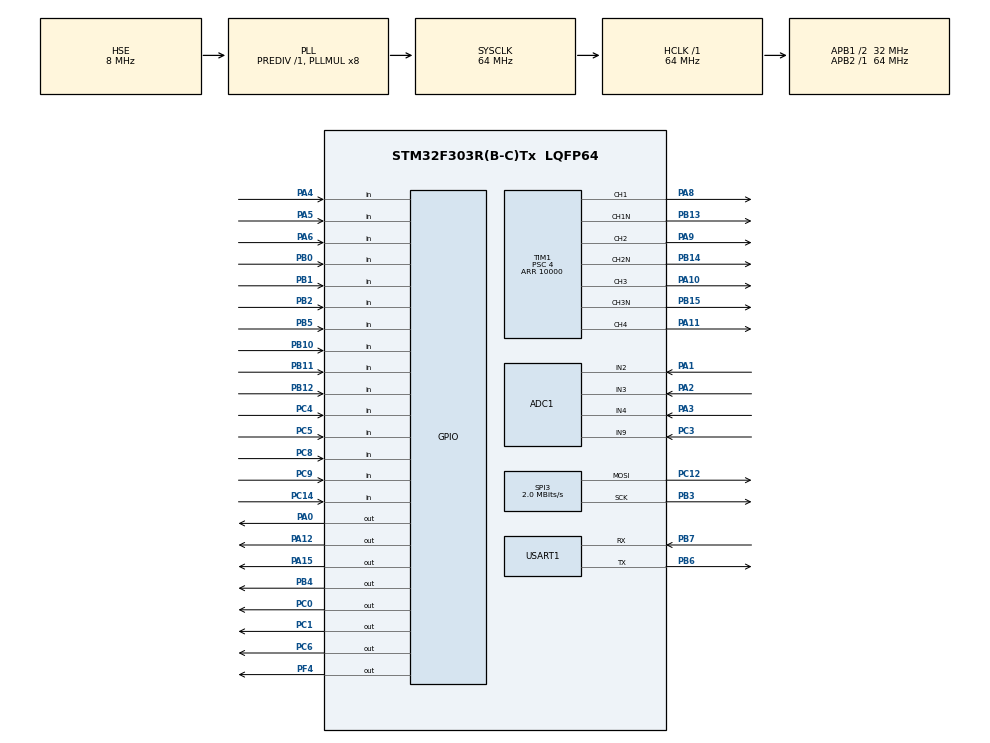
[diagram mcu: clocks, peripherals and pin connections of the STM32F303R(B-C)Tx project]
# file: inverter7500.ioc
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ADC1.Channel-1\#ChannelRegularConversion=ADC_CHANNEL_2
ADC1.ContinuousConvMode=ENABLE
ADC1.NbrOfConversionFlag=1
ADC1.Offset-1\#ChannelRegularConversion=0
ADC1.OffsetNumber-1\#ChannelRegularConversion=ADC_OFFSET_NONE
ADC1.Rank-1\#ChannelRegularConversion=1
ADC1.SamplingTime-1\#ChannelRegularConversion=ADC_SAMPLETIME_1CYCLE_5
ADC1.master=1
Mcu.Family=STM32F3
Mcu.Name=STM32F303R(B-C)Tx
Mcu.Package=LQFP64
NVIC.ADC1_2_IRQn=true\:0\:0\:false\:false\:true\:true\:true
NVIC.PriorityGroup=NVIC_PRIORITYGROUP_4
NVIC.SPI3_IRQn=true\:0\:0\:false\:false\:true\:true\:true
NVIC.TIM1_UP_TIM16_IRQn=true\:0\:0\:false\:false\:true\:true\:true
NVIC.TIM6_DAC_IRQn=true\:0\:0\:false\:false\:true\:true\:true
PA0.Signal=GPIO_Output
PA1.Mode=IN2-Single-Ended
PA1.Signal=ADC1_IN2
PA10.Signal=S_TIM1_CH3
PA11.Signal=S_TIM1_CH4
PA12.Signal=GPIO_Output
PA15.Signal=GPIO_Output
PA2.Mode=IN3-Single-Ended
PA2.Signal=ADC1_IN3
PA3.Mode=IN4-Single-Ended
PA3.Signal=ADC1_IN4
PA4.Signal=GPIO_Input
PA5.Signal=GPIO_Input
PA6.Signal=GPIO_Input
PA8.Signal=S_TIM1_CH1
PA9.Signal=S_TIM1_CH2
PB0.Signal=GPIO_Input
PB1.Signal=GPIO_Input
PB10.Signal=GPIO_Input
PB11.Signal=GPIO_Input
PB12.Signal=GPIO_Input
PB13.Mode=PWM Generation1 CH1 CH1N
PB13.Signal=TIM1_CH1N
PB14.Mode=PWM Generation2 CH2 CH2N
PB14.Signal=TIM1_CH2N
PB15.Mode=PWM Generation3 CH3 CH3N
PB15.Signal=TIM1_CH3N
PB2.Signal=GPIO_Input
PB3.Mode=TX_Only_Simplex_Unidirect_Master
PB3.Signal=SPI3_SCK
PB4.Signal=GPIO_Output
PB5.Signal=GPIO_Input
PB6.Mode=Asynchronous
PB6.Signal=USART1_TX
PB7.Mode=Asynchronous
PB7.Signal=USART1_RX
PC0.Signal=GPIO_Output
PC1.Signal=GPIO_Output
PC12.Mode=TX_Only_Simplex_Unidirect_Master
PC12.Signal=SPI3_MOSI
PC14-OSC32_IN.Signal=GPIO_Input
PC3.Signal=ADCx_IN9
PC4.Signal=GPIO_Input
PC5.Signal=GPIO_Input
PC6.Signal=GPIO_Output
PC8.Signal=GPIO_Input
PC9.Signal=GPIO_Input
PF0-OSC_IN.Mode=HSE-External-Oscillator
PF0-OSC_IN.Signal=RCC_OSC_IN
PF1-OSC_OUT.Mode=HSE-External-Oscillator
PF1-OSC_OUT.Signal=RCC_OSC_OUT
PF4.Signal=GPIO_Output
ProjectManager.HeapSize=0x200
ProjectManager.StackSize=0x400
ProjectManager.TargetToolchain=EWARM V8
RCC.AHBFreq_Value=64000000
RCC.APB1CLKDivider=RCC_HCLK_DIV2
RCC.APB1Freq_Value=32000000
RCC.APB1TimFreq_Value=64000000
RCC.APB2Freq_Value=64000000
RCC.APB2TimFreq_Value=64000000
RCC.CortexFreq_Value=64000000
RCC.EnbaleCSS=true
RCC.HCLKFreq_Value=64000000
RCC.HSE_VALUE=8000000
RCC.HSI_VALUE=8000000
RCC.LSE_VALUE=32768
RCC.PLLMUL=RCC_PLL_MUL8
RCC.PLLSourceVirtual=RCC_PLLSOURCE_HSE
RCC.SYSCLKFreq_VALUE=64000000
RCC.SYSCLKSourceVirtual=RCC_SYSCLKSOURCE_PLLCLK
RCC.USBFreq_Value=64000000
SH.ADCx_IN9.0=ADC1_IN9,IN9-Single-Ended
SH.S_TIM1_CH1.0=TIM1_CH1,PWM Generation1 CH1 CH1N
SH.S_TIM1_CH2.0=TIM1_CH2,PWM Generation2 CH2 CH2N
SH.S_TIM1_CH3.0=TIM1_CH3,PWM Generation3 CH3 CH3N
SH.S_TIM1_CH4.0=TIM1_CH4,PWM Generation4 CH4
SPI3.BaudRatePrescaler=SPI_BAUDRATEPRESCALER_16
SPI3.CLKPhase=SPI_PHASE_1EDGE
SPI3.CLKPolarity=SPI_POLARITY_LOW
SPI3.CalculateBaudRate=2.0 MBits/s
SPI3.DataSize=SPI_DATASIZE_8BIT
SPI3.Direction=SPI_DIRECTION_2LINES
SPI3.Mode=SPI_MODE_MASTER
SPI3.NSSPMode=SPI_NSS_PULSE_DISABLE
SPI3.VirtualType=VM_MASTER
TIM1.AutomaticOutput=TIM_AUTOMATICOUTPUT_DISABLE
TIM1.BreakState=TIM_BREAK_DISABLE
TIM1.Channel-PWM\ Generation1\ CH1\ CH1N=TIM_CHANNEL_1
TIM1.Channel-PWM\ Generation2\ CH2\ CH2N=TIM_CHANNEL_2
TIM1.Channel-PWM\ Generation3\ CH3\ CH3N=TIM_CHANNEL_3
TIM1.Channel-PWM\ Generation4\ CH4=TIM_CHANNEL_4
TIM1.CounterMode=TIM_COUNTERMODE_CENTERALIGNED1
TIM1.Period=10000
TIM1.Prescaler=4
TIM6.AutoReloadPreload=TIM_AUTORELOAD_PRELOAD_ENABLE
TIM6.Period=64000
TIM6.Prescaler=0
TIM6.TIM_MasterOutputTrigger=TIM_TRGO_RESET
USART1.VirtualMode-Asynchronous=VM_ASYNC
VP_TIM1_VS_ClockSourceINT.Mode=Internal
VP_TIM6_VS_ClockSourceINT.Mode=Enable_Timer
board=custom

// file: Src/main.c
// linking branch edit
/* USER CODE BEGIN Header */
/**
  ******************************************************************************
  * @file           : main.c
  * @brief          : Main program body
  ******************************************************************************
  * @attention
  *
  * <h2><center>&copy; Copyright (c) 2019 STMicroelectronics.
  * All rights reserved.</center></h2>
  *
  * This software component is licensed by ST under BSD 3-Clause license,
  * the "License"; You may not use this file except in compliance with the
  * License. You may obtain a copy of the License at:
  *                        opensource.org/licenses/BSD-3-Clause
  *
  ******************************************************************************
  */
/* USER CODE END Header */ //master edit

#include "main.h"

/* USER CODE BEGIN Includes */
#include "MOTOR\motor_control.h"
/* USER CODE END Includes */

ADC_HandleTypeDef hadc1;

SPI_HandleTypeDef hspi3;

TIM_HandleTypeDef htim1;
TIM_HandleTypeDef htim6;

UART_HandleTypeDef huart1;

void SystemClock_Config(void);
static void MX_GPIO_Init(void);
static void MX_ADC1_Init(void);
static void MX_TIM1_Init(void);
static void MX_TIM6_Init(void);
static void MX_USART1_UART_Init(void);
static void MX_SPI3_Init(void);

int main(void)
{

  /* MCU Configuration--------------------------------------------------------*/

  /* Reset of all peripherals, Initializes the Flash interface and the Systick. */
  HAL_Init();

  /* Configure the system clock */
  SystemClock_Config();

  /* Initialize all configured peripherals */
  MX_GPIO_Init();
  MX_ADC1_Init();
  MX_TIM1_Init();
  MX_TIM6_Init();
  MX_USART1_UART_Init();
  MX_SPI3_Init();
  /* USER CODE BEGIN 2 */

  GPIO_InitTypeDef GPIO_InitStruct = {0};
/*Configure GPIO pin : PB4 */
  GPIO_InitStruct.Pin = GPIO_PIN_4;
  GPIO_InitStruct.Mode = GPIO_MODE_OUTPUT_OD;
  GPIO_InitStruct.Pull = GPIO_NOPULL;
  GPIO_InitStruct.Speed = GPIO_SPEED_FREQ_LOW;
  HAL_GPIO_Init(GPIOB, &GPIO_InitStruct);

  HAL_TIM_Base_Start_IT(&htim6);

  /* USER CODE END 2 */

  /* Infinite loop */
  /* USER CODE BEGIN WHILE */
  //GPIOC_OTYPER=GPIOC_OTYPER | 0x100;
//  led_7segment_data[2]=0x1F;
  led_7segment_data[1]=0x0F;
  led_7segment_data[0]=0x0F;

  while (1)
  {

  //HAL_GPIO_TogglePin (GPIOF, GPIO_PIN_4);

  //  HAL_GPIO_WritePin(GPIOF, GPIO_PIN_4, GPIO_PIN_RESET);
  //HAL_Delay (1000);
  // HAL_GPIO_WritePin(GPIOF, GPIO_PIN_4, GPIO_PIN_SET);
  // HAL_Delay(1000);
  //  highbit_led_7segment_data=0x77;
  //HAL_GPIO_TogglePin(GPIOB, GPIO_PIN_4);
  //  HAL_Delay(10);
 // HAL_SPI_Transmit_IT(&hspi3, (uint8_t*) (led_7segment_data), 2);

  HAL_SPI_Transmit_IT(&hspi3, &led_7segment_data[0], 1);
   //   HAL_Delay(1);
  HAL_GPIO_WritePin(GPIOF, GPIO_PIN_4, GPIO_PIN_SET);
  //HAL_GPIO_WritePin(GPIOF, GPIO_PIN_4, GPIO_PIN_RESET);
  HAL_SPI_Transmit_IT(&hspi3, &led_7segment_data[1], 1);
//  HAL_GPIO_WritePin(GPIOF, GPIO_PIN_4, GPIO_PIN_SET);
  HAL_GPIO_WritePin(GPIOF, GPIO_PIN_4, GPIO_PIN_RESET);

  //HAL_GPIO_TogglePin(GPIOF, GPIO_PIN_4);
  //  HAL_Delay(1);
  //HAL_GPIO_WritePin(GPIOB, GPIO_PIN_4, GPIO_PIN_SET);
  //HAL_Delay(1);

  //HAL_Delay(1);

  //  if (highbit_led_7segment_data==0xAA) highbit_led_7segment_data=0x55;
  // else highbit_led_7segment_data=0xAA;

    /* USER CODE END WHILE */

  }
}

void SystemClock_Config(void)
{
  RCC_OscInitTypeDef RCC_OscInitStruct = {0};
  RCC_ClkInitTypeDef RCC_ClkInitStruct = {0};
  RCC_PeriphCLKInitTypeDef PeriphClkInit = {0};

  /** Initializes the CPU, AHB and APB busses clocks
  */
  RCC_OscInitStruct.OscillatorType = RCC_OSCILLATORTYPE_HSE;
  RCC_OscInitStruct.HSEState = RCC_HSE_ON;
  RCC_OscInitStruct.HSEPredivValue = RCC_HSE_PREDIV_DIV1;
  RCC_OscInitStruct.HSIState = RCC_HSI_ON;
  RCC_OscInitStruct.PLL.PLLState = RCC_PLL_ON;
  RCC_OscInitStruct.PLL.PLLSource = RCC_PLLSOURCE_HSE;
  RCC_OscInitStruct.PLL.PLLMUL = RCC_PLL_MUL8;
  if (HAL_RCC_OscConfig(&RCC_OscInitStruct) != HAL_OK)
  {
    Error_Handler();
  }
  /** Initializes the CPU, AHB and APB busses clocks
  */
  RCC_ClkInitStruct.ClockType = RCC_CLOCKTYPE_HCLK|RCC_CLOCKTYPE_SYSCLK
                              |RCC_CLOCKTYPE_PCLK1|RCC_CLOCKTYPE_PCLK2;
  RCC_ClkInitStruct.SYSCLKSource = RCC_SYSCLKSOURCE_PLLCLK;
  RCC_ClkInitStruct.AHBCLKDivider = RCC_SYSCLK_DIV1;
  RCC_ClkInitStruct.APB1CLKDivider = RCC_HCLK_DIV2;
  RCC_ClkInitStruct.APB2CLKDivider = RCC_HCLK_DIV1;

  if (HAL_RCC_ClockConfig(&RCC_ClkInitStruct, FLASH_LATENCY_2) != HAL_OK)
  {
    Error_Handler();
  }
  PeriphClkInit.PeriphClockSelection = RCC_PERIPHCLK_USART1|RCC_PERIPHCLK_TIM1
                              |RCC_PERIPHCLK_ADC12;
  PeriphClkInit.Usart1ClockSelection = RCC_USART1CLKSOURCE_PCLK2;
  PeriphClkInit.Adc12ClockSelection = RCC_ADC12PLLCLK_DIV1;
  PeriphClkInit.Tim1ClockSelection = RCC_TIM1CLK_HCLK;
  if (HAL_RCCEx_PeriphCLKConfig(&PeriphClkInit) != HAL_OK)
  {
    Error_Handler();
  }
  /** Enables the Clock Security System
  */
  HAL_RCC_EnableCSS();
}

static void MX_ADC1_Init(void)
{

  ADC_MultiModeTypeDef multimode = {0};
  ADC_ChannelConfTypeDef sConfig = {0};

  /** Common config
  */
  hadc1.Instance = ADC1;
  hadc1.Init.ClockPrescaler = ADC_CLOCK_ASYNC_DIV1;
  hadc1.Init.Resolution = ADC_RESOLUTION_12B;
  hadc1.Init.ScanConvMode = ADC_SCAN_DISABLE;
  hadc1.Init.ContinuousConvMode = ENABLE;
  hadc1.Init.DiscontinuousConvMode = DISABLE;
  hadc1.Init.ExternalTrigConvEdge = ADC_EXTERNALTRIGCONVEDGE_NONE;
  hadc1.Init.ExternalTrigConv = ADC_SOFTWARE_START;
  hadc1.Init.DataAlign = ADC_DATAALIGN_RIGHT;
  hadc1.Init.NbrOfConversion = 1;
  hadc1.Init.DMAContinuousRequests = DISABLE;
  hadc1.Init.EOCSelection = ADC_EOC_SINGLE_CONV;
  hadc1.Init.LowPowerAutoWait = DISABLE;
  hadc1.Init.Overrun = ADC_OVR_DATA_OVERWRITTEN;
  if (HAL_ADC_Init(&hadc1) != HAL_OK)
  {
    Error_Handler();
  }
  /** Configure the ADC multi-mode
  */
  multimode.Mode = ADC_MODE_INDEPENDENT;
  if (HAL_ADCEx_MultiModeConfigChannel(&hadc1, &multimode) != HAL_OK)
  {
    Error_Handler();
  }
  /** Configure Regular Channel
  */
  sConfig.Channel = ADC_CHANNEL_2;
  sConfig.Rank = ADC_REGULAR_RANK_1;
  sConfig.SingleDiff = ADC_SINGLE_ENDED;
  sConfig.SamplingTime = ADC_SAMPLETIME_1CYCLE_5;
  sConfig.OffsetNumber = ADC_OFFSET_NONE;
  sConfig.Offset = 0;
  if (HAL_ADC_ConfigChannel(&hadc1, &sConfig) != HAL_OK)
  {
    Error_Handler();
  }

}

static void MX_SPI3_Init(void)
{

  /* SPI3 parameter configuration*/
  hspi3.Instance = SPI3;
  hspi3.Init.Mode = SPI_MODE_MASTER;
  hspi3.Init.Direction = SPI_DIRECTION_2LINES;
  hspi3.Init.DataSize = SPI_DATASIZE_8BIT;
  hspi3.Init.CLKPolarity = SPI_POLARITY_LOW;
  hspi3.Init.CLKPhase = SPI_PHASE_1EDGE;
  hspi3.Init.NSS = SPI_NSS_SOFT;
  hspi3.Init.BaudRatePrescaler = SPI_BAUDRATEPRESCALER_16;
  hspi3.Init.FirstBit = SPI_FIRSTBIT_MSB;
  hspi3.Init.TIMode = SPI_TIMODE_DISABLE;
  hspi3.Init.CRCCalculation = SPI_CRCCALCULATION_DISABLE;
  hspi3.Init.CRCPolynomial = 7;
  hspi3.Init.CRCLength = SPI_CRC_LENGTH_DATASIZE;
  hspi3.Init.NSSPMode = SPI_NSS_PULSE_DISABLE;
  if (HAL_SPI_Init(&hspi3) != HAL_OK)
  {
    Error_Handler();
  }

}

static void MX_TIM1_Init(void)
{

  TIM_ClockConfigTypeDef sClockSourceConfig = {0};
  TIM_MasterConfigTypeDef sMasterConfig = {0};
  TIM_OC_InitTypeDef sConfigOC = {0};
  TIM_BreakDeadTimeConfigTypeDef sBreakDeadTimeConfig = {0};

  htim1.Instance = TIM1;
  htim1.Init.Prescaler = 4;
  htim1.Init.CounterMode = TIM_COUNTERMODE_CENTERALIGNED1;
  htim1.Init.Period = 10000;
  htim1.Init.ClockDivision = TIM_CLOCKDIVISION_DIV1;
  htim1.Init.RepetitionCounter = 0;
  htim1.Init.AutoReloadPreload = TIM_AUTORELOAD_PRELOAD_DISABLE;
  if (HAL_TIM_Base_Init(&htim1) != HAL_OK)
  {
    Error_Handler();
  }
  sClockSourceConfig.ClockSource = TIM_CLOCKSOURCE_INTERNAL;
  if (HAL_TIM_ConfigClockSource(&htim1, &sClockSourceConfig) != HAL_OK)
  {
    Error_Handler();
  }
  if (HAL_TIM_PWM_Init(&htim1) != HAL_OK)
  {
    Error_Handler();
  }
  sMasterConfig.MasterOutputTrigger = TIM_TRGO_RESET;
  sMasterConfig.MasterOutputTrigger2 = TIM_TRGO2_RESET;
  sMasterConfig.MasterSlaveMode = TIM_MASTERSLAVEMODE_DISABLE;
  if (HAL_TIMEx_MasterConfigSynchronization(&htim1, &sMasterConfig) != HAL_OK)
  {
    Error_Handler();
  }
  sConfigOC.OCMode = TIM_OCMODE_PWM1;
  sConfigOC.Pulse = 0;
  sConfigOC.OCPolarity = TIM_OCPOLARITY_HIGH;
  sConfigOC.OCNPolarity = TIM_OCNPOLARITY_HIGH;
  sConfigOC.OCFastMode = TIM_OCFAST_DISABLE;
  sConfigOC.OCIdleState = TIM_OCIDLESTATE_RESET;
  sConfigOC.OCNIdleState = TIM_OCNIDLESTATE_RESET;
  if (HAL_TIM_PWM_ConfigChannel(&htim1, &sConfigOC, TIM_CHANNEL_1) != HAL_OK)
  {
    Error_Handler();
  }
  if (HAL_TIM_PWM_ConfigChannel(&htim1, &sConfigOC, TIM_CHANNEL_2) != HAL_OK)
  {
    Error_Handler();
  }
  if (HAL_TIM_PWM_ConfigChannel(&htim1, &sConfigOC, TIM_CHANNEL_3) != HAL_OK)
  {
    Error_Handler();
  }
  if (HAL_TIM_PWM_ConfigChannel(&htim1, &sConfigOC, TIM_CHANNEL_4) != HAL_OK)
  {
    Error_Handler();
  }
  sBreakDeadTimeConfig.OffStateRunMode = TIM_OSSR_DISABLE;
  sBreakDeadTimeConfig.OffStateIDLEMode = TIM_OSSI_DISABLE;
  sBreakDeadTimeConfig.LockLevel = TIM_LOCKLEVEL_OFF;
  sBreakDeadTimeConfig.DeadTime = 0;
  sBreakDeadTimeConfig.BreakState = TIM_BREAK_DISABLE;
  sBreakDeadTimeConfig.BreakPolarity = TIM_BREAKPOLARITY_HIGH;
  sBreakDeadTimeConfig.BreakFilter = 0;
  sBreakDeadTimeConfig.Break2State = TIM_BREAK2_DISABLE;
  sBreakDeadTimeConfig.Break2Polarity = TIM_BREAK2POLARITY_HIGH;
  sBreakDeadTimeConfig.Break2Filter = 0;
  sBreakDeadTimeConfig.AutomaticOutput = TIM_AUTOMATICOUTPUT_DISABLE;
  if (HAL_TIMEx_ConfigBreakDeadTime(&htim1, &sBreakDeadTimeConfig) != HAL_OK)
  {
    Error_Handler();
  }
  HAL_TIM_MspPostInit(&htim1);

}

static void MX_TIM6_Init(void)
{

  TIM_MasterConfigTypeDef sMasterConfig = {0};

  htim6.Instance = TIM6;
  htim6.Init.Prescaler = 0;
  htim6.Init.CounterMode = TIM_COUNTERMODE_UP;
  htim6.Init.Period = 64000;
  htim6.Init.AutoReloadPreload = TIM_AUTORELOAD_PRELOAD_ENABLE;
  if (HAL_TIM_Base_Init(&htim6) != HAL_OK)
  {
    Error_Handler();
  }
  sMasterConfig.MasterOutputTrigger = TIM_TRGO_RESET;
  sMasterConfig.MasterSlaveMode = TIM_MASTERSLAVEMODE_DISABLE;
  if (HAL_TIMEx_MasterConfigSynchronization(&htim6, &sMasterConfig) != HAL_OK)
  {
    Error_Handler();
  }

}

static void MX_USART1_UART_Init(void)
{

  huart1.Instance = USART1;
  huart1.Init.BaudRate = 38400;
  huart1.Init.WordLength = UART_WORDLENGTH_8B;
  huart1.Init.StopBits = UART_STOPBITS_1;
  huart1.Init.Parity = UART_PARITY_NONE;
  huart1.Init.Mode = UART_MODE_TX_RX;
  huart1.Init.HwFlowCtl = UART_HWCONTROL_NONE;
  huart1.Init.OverSampling = UART_OVERSAMPLING_16;
  huart1.Init.OneBitSampling = UART_ONE_BIT_SAMPLE_DISABLE;
  huart1.AdvancedInit.AdvFeatureInit = UART_ADVFEATURE_NO_INIT;
  if (HAL_UART_Init(&huart1) != HAL_OK)
  {
    Error_Handler();
  }

}

static void MX_GPIO_Init(void)
{
  GPIO_InitTypeDef GPIO_InitStruct = {0};

  /* GPIO Ports Clock Enable */
  __HAL_RCC_GPIOC_CLK_ENABLE();
  __HAL_RCC_GPIOF_CLK_ENABLE();
  __HAL_RCC_GPIOA_CLK_ENABLE();
  __HAL_RCC_GPIOB_CLK_ENABLE();

  /*Configure GPIO pin Output Level */
  HAL_GPIO_WritePin(GPIOC, GPIO_PIN_0|GPIO_PIN_1|GPIO_PIN_6, GPIO_PIN_RESET);

  /*Configure GPIO pin Output Level */
  HAL_GPIO_WritePin(GPIOA, GPIO_PIN_0|GPIO_PIN_12|GPIO_PIN_15, GPIO_PIN_RESET);

  /*Configure GPIO pin Output Level */
  HAL_GPIO_WritePin(GPIOF, GPIO_PIN_4, GPIO_PIN_RESET);

  /*Configure GPIO pin Output Level */
  HAL_GPIO_WritePin(GPIOB, GPIO_PIN_4, GPIO_PIN_RESET);

  /*Configure GPIO pins : PC14 PC4 PC5 PC8
                           PC9 */
  GPIO_InitStruct.Pin = GPIO_PIN_14|GPIO_PIN_4|GPIO_PIN_5|GPIO_PIN_8
                          |GPIO_PIN_9;
  GPIO_InitStruct.Mode = GPIO_MODE_INPUT;
  GPIO_InitStruct.Pull = GPIO_NOPULL;
  HAL_GPIO_Init(GPIOC, &GPIO_InitStruct);

  /*Configure GPIO pins : PC0 PC1 PC6 */
  GPIO_InitStruct.Pin = GPIO_PIN_0|GPIO_PIN_1|GPIO_PIN_6;
  GPIO_InitStruct.Mode = GPIO_MODE_OUTPUT_PP;
  GPIO_InitStruct.Pull = GPIO_NOPULL;
  GPIO_InitStruct.Speed = GPIO_SPEED_FREQ_LOW;
  HAL_GPIO_Init(GPIOC, &GPIO_InitStruct);

  /*Configure GPIO pins : PA0 PA12 PA15 */
  GPIO_InitStruct.Pin = GPIO_PIN_0|GPIO_PIN_12|GPIO_PIN_15;
  GPIO_InitStruct.Mode = GPIO_MODE_OUTPUT_PP;
  GPIO_InitStruct.Pull = GPIO_NOPULL;
  GPIO_InitStruct.Speed = GPIO_SPEED_FREQ_LOW;
  HAL_GPIO_Init(GPIOA, &GPIO_InitStruct);

  /*Configure GPIO pin : PF4 */
  GPIO_InitStruct.Pin = GPIO_PIN_4;
  GPIO_InitStruct.Mode = GPIO_MODE_OUTPUT_PP;
  GPIO_InitStruct.Pull = GPIO_NOPULL;
  GPIO_InitStruct.Speed = GPIO_SPEED_FREQ_LOW;
  HAL_GPIO_Init(GPIOF, &GPIO_InitStruct);

  /*Configure GPIO pins : PA4 PA5 PA6 */
  GPIO_InitStruct.Pin = GPIO_PIN_4|GPIO_PIN_5|GPIO_PIN_6;
  GPIO_InitStruct.Mode = GPIO_MODE_INPUT;
  GPIO_InitStruct.Pull = GPIO_NOPULL;
  HAL_GPIO_Init(GPIOA, &GPIO_InitStruct);

  /*Configure GPIO pins : PB0 PB1 PB2 PB10
                           PB11 PB12 PB5 */
  GPIO_InitStruct.Pin = GPIO_PIN_0|GPIO_PIN_1|GPIO_PIN_2|GPIO_PIN_10
                          |GPIO_PIN_11|GPIO_PIN_12|GPIO_PIN_5;
  GPIO_InitStruct.Mode = GPIO_MODE_INPUT;
  GPIO_InitStruct.Pull = GPIO_NOPULL;
  HAL_GPIO_Init(GPIOB, &GPIO_InitStruct);

  /*Configure GPIO pin : PB4 */
  GPIO_InitStruct.Pin = GPIO_PIN_4;
  GPIO_InitStruct.Mode = GPIO_MODE_OUTPUT_PP;
  GPIO_InitStruct.Pull = GPIO_NOPULL;
  GPIO_InitStruct.Speed = GPIO_SPEED_FREQ_LOW;
  HAL_GPIO_Init(GPIOB, &GPIO_InitStruct);

}

void Error_Handler(void)
{
}

/************************ (C) COPYRIGHT STMicroelectronics *****END OF FILE****/
